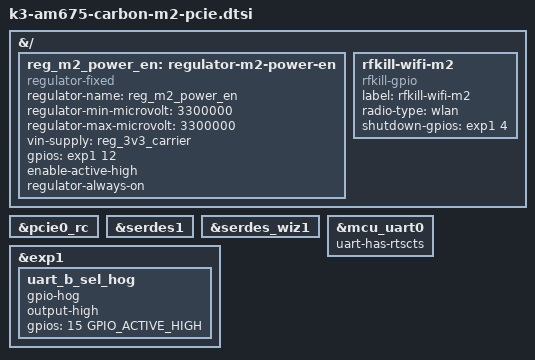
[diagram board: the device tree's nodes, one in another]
// SPDX-License-Identifier: GPL-2.0
/*
 * M.2 PCIE Wi-Fi common functions
 *
 * Copyright (C) 2025 Ezurio LLC
 */

#include <dt-bindings/gpio/gpio.h>

&{/} {
	reg_m2_power_en: regulator-m2-power-en {
		compatible = "regulator-fixed";
		regulator-name = "reg_m2_power_en";
		regulator-min-microvolt = <3300000>;
		regulator-max-microvolt = <3300000>;

		vin-supply = <&reg_3v3_carrier>;

		gpios = <&exp1 12 GPIO_ACTIVE_HIGH>;  /* M2_POWER_EN */
		enable-active-high;

		regulator-always-on;
	};

	rfkill-wifi-m2 {
		compatible = "rfkill-gpio";
		label = "rfkill-wifi-m2";
		radio-type = "wlan";
		shutdown-gpios = <&exp1 4 GPIO_ACTIVE_HIGH>; /* M2_WDISABLE1# */
	};
};

&pcie0_rc {
	status = "okay";
};

&serdes1 {
	status = "okay";
};

&serdes_wiz1 {
	status = "okay";
};

&mcu_uart0 {
	status = "okay";

	uart-has-rtscts;
};

&exp1 {
	uart_b_sel_hog {
		gpio-hog;
		output-high;
		gpios = <15 GPIO_ACTIVE_HIGH>;
	};
};
